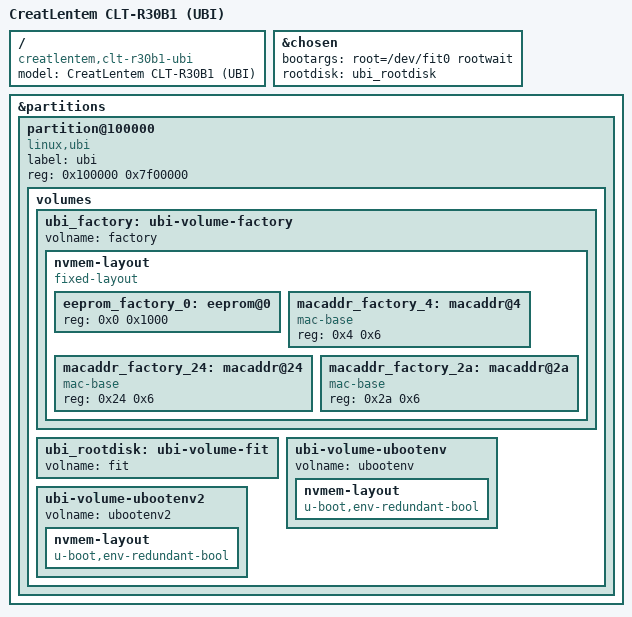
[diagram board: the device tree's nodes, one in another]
// SPDX-License-Identifier: GPL-2.0-or-later OR MIT

#include "mt7981b-creatlentem-clt-r30b1-common.dtsi"

/ {
	model = "CreatLentem CLT-R30B1 (UBI)";
	compatible = "creatlentem,clt-r30b1-ubi", "mediatek,mt7981";
};

&chosen {
	bootargs = "root=/dev/fit0 rootwait";
	rootdisk = <&ubi_rootdisk>;
};

&partitions {
	partition@100000 {
		label = "ubi";
		reg = <0x100000 0x7f00000>;
		compatible = "linux,ubi";

		volumes {
			ubi_factory: ubi-volume-factory {
				volname = "factory";
			};

			ubi_rootdisk: ubi-volume-fit {
				volname = "fit";
			};

			ubi-volume-ubootenv {
				volname = "ubootenv";
				nvmem-layout {
					compatible = "u-boot,env-redundant-bool";
				};
			};

			ubi-volume-ubootenv2 {
				volname = "ubootenv2";
				nvmem-layout {
					compatible = "u-boot,env-redundant-bool";
				};
			};
		};
	};
};

&ubi_factory {
	nvmem-layout {
		compatible = "fixed-layout";
		#address-cells = <1>;
		#size-cells = <1>;

		eeprom_factory_0: eeprom@0 {
			reg = <0x0 0x1000>;
		};

		macaddr_factory_4: macaddr@4 {
			compatible = "mac-base";
			reg = <0x4 0x6>;
			#nvmem-cell-cells = <1>;
		};

		macaddr_factory_24: macaddr@24 {
			compatible = "mac-base";
			reg = <0x24 0x6>;
			#nvmem-cell-cells = <1>;
		};

		macaddr_factory_2a: macaddr@2a {
			compatible = "mac-base";
			reg = <0x2a 0x6>;
			#nvmem-cell-cells = <1>;
		};
	};
};
